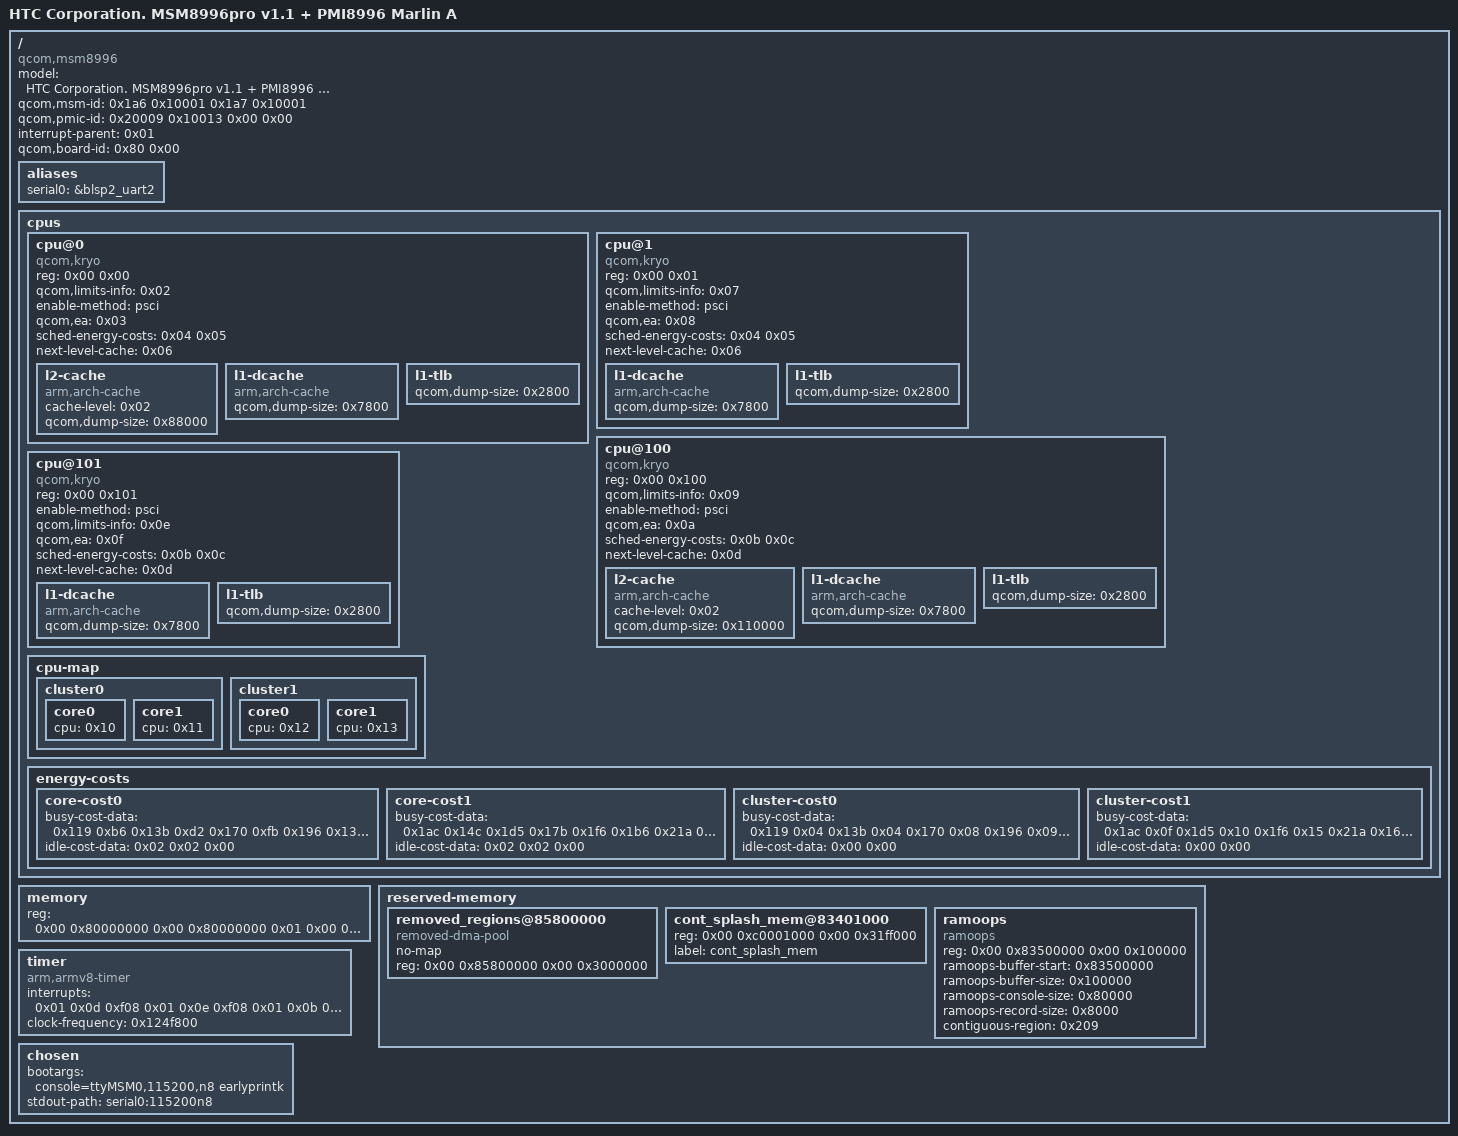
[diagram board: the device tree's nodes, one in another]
// SPDX-License-Identifier: GPL-2.0-only
/*
 * Copyright (c) 2022, Shuxiang Fan <linclonfan@outlook.com>
 */

/dts-v1/;

#include "msm8996pro.dtsi"
#include "pm8994.dtsi"
#include "pmi8994.dtsi"
/{
    #address-cells = <0x02>;
	#size-cells = <0x02>;
	model = "HTC Corporation. MSM8996pro v1.1 + PMI8996 Marlin A";
	compatible = "qcom,msm8996";
	qcom,msm-id = <0x1a6 0x10001 0x1a7 0x10001>;
	qcom,pmic-id = <0x20009 0x10013 0x00 0x00>;
	interrupt-parent = <0x01>;
	qcom,board-id = <0x80 0x00>;

	aliases {
		serial0 = &blsp2_uart2;
	};
	
    cpus {
		#address-cells = <0x02>;
		#size-cells = <0x00>;

		cpu@0 {
			device_type = "cpu";
			compatible = "qcom,kryo";
			reg = <0x00 0x00>;
			qcom,limits-info = <0x02>;
			enable-method = "psci";
			qcom,ea = <0x03>;
			sched-energy-costs = <0x04 0x05>;
			next-level-cache = <0x06>;
			linux,phandle = <0x10>;
			phandle = <0x10>;

			l2-cache {
				compatible = "arm,arch-cache";
				cache-level = <0x02>;
				qcom,dump-size = <0x88000>;
				linux,phandle = <0x06>;
				phandle = <0x06>;
			};

			l1-dcache {
				compatible = "arm,arch-cache";
				qcom,dump-size = <0x7800>;
				linux,phandle = <0x16f>;
				phandle = <0x16f>;
			};

			l1-tlb {
				qcom,dump-size = <0x2800>;
				linux,phandle = <0x173>;
				phandle = <0x173>;
			};
		};

		cpu@1 {
			device_type = "cpu";
			compatible = "qcom,kryo";
			reg = <0x00 0x01>;
			qcom,limits-info = <0x07>;
			enable-method = "psci";
			qcom,ea = <0x08>;
			sched-energy-costs = <0x04 0x05>;
			next-level-cache = <0x06>;
			linux,phandle = <0x11>;
			phandle = <0x11>;

			l1-dcache {
				compatible = "arm,arch-cache";
				qcom,dump-size = <0x7800>;
				linux,phandle = <0x170>;
				phandle = <0x170>;
			};

			l1-tlb {
				qcom,dump-size = <0x2800>;
				linux,phandle = <0x174>;
				phandle = <0x174>;
			};
		};

		cpu@100 {
			device_type = "cpu";
			compatible = "qcom,kryo";
			reg = <0x00 0x100>;
			qcom,limits-info = <0x09>;
			enable-method = "psci";
			qcom,ea = <0x0a>;
			sched-energy-costs = <0x0b 0x0c>;
			next-level-cache = <0x0d>;
			linux,phandle = <0x12>;
			phandle = <0x12>;

			l2-cache {
				compatible = "arm,arch-cache";
				cache-level = <0x02>;
				qcom,dump-size = <0x110000>;
				linux,phandle = <0x0d>;
				phandle = <0x0d>;
			};

			l1-dcache {
				compatible = "arm,arch-cache";
				qcom,dump-size = <0x7800>;
				linux,phandle = <0x171>;
				phandle = <0x171>;
			};

			l1-tlb {
				qcom,dump-size = <0x2800>;
				linux,phandle = <0x175>;
				phandle = <0x175>;
			};
		};

		cpu@101 {
			device_type = "cpu";
			compatible = "qcom,kryo";
			reg = <0x00 0x101>;
			enable-method = "psci";
			qcom,limits-info = <0x0e>;
			qcom,ea = <0x0f>;
			sched-energy-costs = <0x0b 0x0c>;
			next-level-cache = <0x0d>;
			linux,phandle = <0x13>;
			phandle = <0x13>;

			l1-dcache {
				compatible = "arm,arch-cache";
				qcom,dump-size = <0x7800>;
				linux,phandle = <0x172>;
				phandle = <0x172>;
			};

			l1-tlb {
				qcom,dump-size = <0x2800>;
				linux,phandle = <0x176>;
				phandle = <0x176>;
			};
		};

		cpu-map {

			cluster0 {

				core0 {
					cpu = <0x10>;
				};

				core1 {
					cpu = <0x11>;
				};
			};

			cluster1 {

				core0 {
					cpu = <0x12>;
				};

				core1 {
					cpu = <0x13>;
				};
			};
		};

		energy-costs {

			core-cost0 {
				busy-cost-data = <0x119 0xb6 0x13b 0xd2 0x170 0xfb 0x196 0x132 0x1ac 0x14c 0x1d5 0x17b 0x1f6 0x1b6 0x21a 0x1ee 0x245 0x226 0x263 0x265 0x288 0x29e 0x2ac 0x2f0 0x2d9 0x350 0x2fb 0x39d>;
				idle-cost-data = <0x02 0x02 0x00>;
				linux,phandle = <0x04>;
				phandle = <0x04>;
			};

			core-cost1 {
				busy-cost-data = <0x1ac 0x14c 0x1d5 0x17b 0x1f6 0x1b6 0x21a 0x1ee 0x245 0x226 0x263 0x265 0x288 0x29e 0x2ac 0x2f0 0x2d9 0x350 0x2fb 0x39d 0x31b 0x3fa 0x340 0x431 0x364 0x4b9 0x389 0x512 0x3b8 0x594 0x3d3 0x5f1 0x400 0x6b3>;
				idle-cost-data = <0x02 0x02 0x00>;
				linux,phandle = <0x0b>;
				phandle = <0x0b>;
			};

			cluster-cost0 {
				busy-cost-data = <0x119 0x04 0x13b 0x04 0x170 0x08 0x196 0x09 0x1ac 0x0f 0x1d5 0x10 0x1f6 0x15 0x21a 0x16 0x245 0x1d 0x263 0x20 0x288 0x2a 0x2ac 0x31 0x2d9 0x29 0x2fb 0x34>;
				idle-cost-data = <0x00 0x00>;
				linux,phandle = <0x05>;
				phandle = <0x05>;
			};

			cluster-cost1 {
				busy-cost-data = <0x1ac 0x0f 0x1d5 0x10 0x1f6 0x15 0x21a 0x16 0x245 0x1d 0x263 0x20 0x288 0x2a 0x2ac 0x31 0x2d9 0x29 0x2fb 0x34 0x31b 0x3e 0x340 0x45 0x364 0x4b 0x389 0x51 0x3b8 0x5a 0x3d3 0x5d 0x400 0x60>;
				idle-cost-data = <0x00 0x00>;
				linux,phandle = <0x0c>;
				phandle = <0x0c>;
			};
		};
	};

	memory {
		device_type = "memory";
		reg = <0x00 0x80000000 0x00 0x80000000 0x01 0x00 0x00 0x7e550000>;
	};

    reserved-memory {
		#address-cells = <0x02>;
		#size-cells = <0x02>;
		ranges;

		removed_regions@85800000 {
			compatible = "removed-dma-pool";
			no-map;
			reg = <0x00 0x85800000 0x00 0x3000000>;
		};

		cont_splash_mem@83401000 {
			reg = <0x00 0xc0001000 0x00 0x31ff000>;
			label = "cont_splash_mem";
			linux,phandle = <0x1c>;
			phandle = <0x1c>;
		};

		ramoops {
			compatible = "ramoops";
			reg = <0x00 0x83500000 0x00 0x100000>;
			ramoops-buffer-start = <0x83500000>;
			ramoops-buffer-size = <0x100000>;
			ramoops-console-size = <0x80000>;
			ramoops-record-size = <0x8000>;
			contiguous-region = <0x209>;
		};
	};

	timer {
		compatible = "arm,armv8-timer";
		interrupts = <0x01 0x0d 0xf08 0x01 0x0e 0xf08 0x01 0x0b 0xf08 0x01 0x0a 0xf08>;
		clock-frequency = <0x124f800>;
	};

	chosen{
		bootargs = "console=ttyMSM0,115200,n8 earlyprintk";
		stdout-path = "serial0:115200n8";
	};

};
